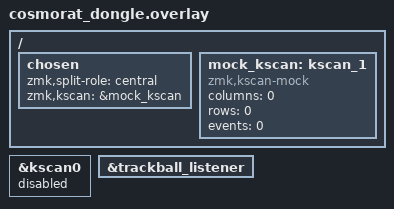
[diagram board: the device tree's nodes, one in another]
#include "cosmorat.dtsi"
#include <input/processors.dtsi>
#include <dt-bindings/zmk/input_transform.h>
#include <zephyr/dt-bindings/input/input-event-codes.h>

/ {
    chosen {
        zmk,split-role = "central";
        zmk,kscan = &mock_kscan;
    };

    mock_kscan: kscan_1 {
        compatible = "zmk,kscan-mock";
        columns = <0>;
        rows = <0>;
        events = <0>;
    };
};

&kscan0 {
    status = "disabled";
};

&trackball_listener {
    status = "okay";
};
